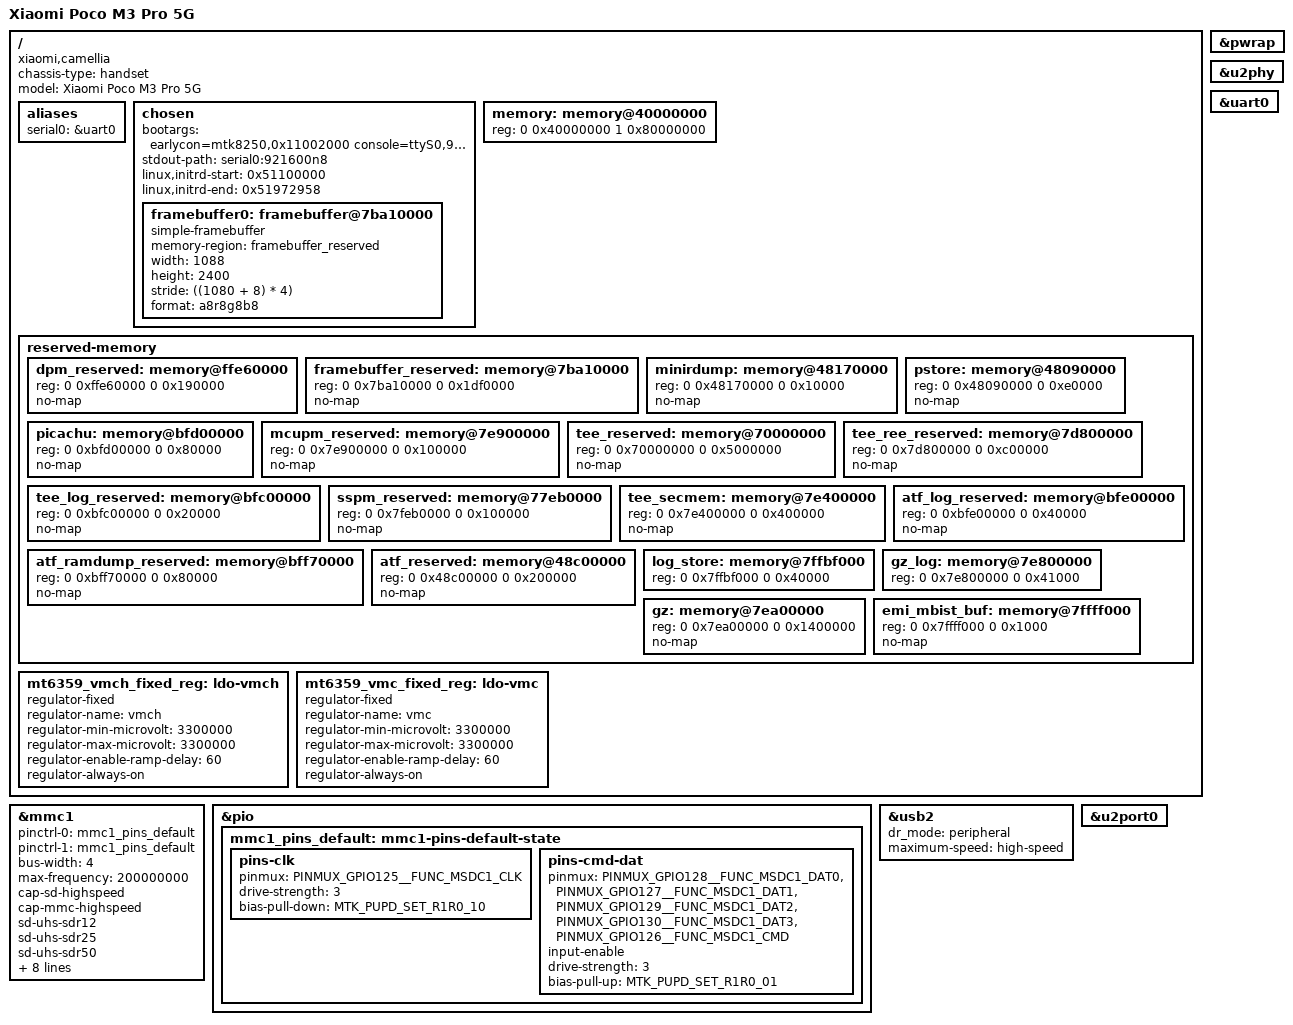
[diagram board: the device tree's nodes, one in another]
// SPDX-License-Identifier: GPL-2.0
/*
 * Device Tree Source for Xiaomi Poco M3 Pro 5G // (camellia)
 * 
 * !NEEDS TESTING FROM SIMILLAR DEVICE = Xiaomi Redmi Mote 10 Pro 5G // (camellian)
 *
 * Copyright (c) Ryo "evilMyQueen" Yamada <evilMyQueen@mainlining.org>
 */

/dts-v1/;

#include <dt-bindings/gpio/gpio.h>
#include <dt-bindings/iio/adc/mediatek,mt6370_adc.h>
#include <dt-bindings/input/input.h>
#include <dt-bindings/leds/common.h>
#include <dt-bindings/pinctrl/mediatek,mt6833-pinfunc.h>

#include "mt6833.dtsi"
#include "mt6359.dtsi"

/ {
	chassis-type = "handset";
	compatible = "xiaomi,camellia", "mediatek,mt6833";
	model = "Xiaomi Poco M3 Pro 5G";

	aliases {
		serial0 = &uart0;
	};

	chosen {
		#address-cells = <2>;
		#size-cells = <2>;
		ranges;

		bootargs = "earlycon=mtk8250,0x11002000 console=ttyS0,921600n1 console=tty0 console=ttyGS0 clk_ignore_unused regulator_ignore_unused pd_ignore_unused PMOS_NOSPLASH";
		stdout-path = "serial0:921600n8";
		linux,initrd-start = <0x51100000>;
		linux,initrd-end = <0x51972958>;
		
		framebuffer0: framebuffer@7ba10000 {
			compatible = "simple-framebuffer";
			memory-region = <&framebuffer_reserved>;
			width = <1088>;
			height = <2400>;
			stride = <((1080 + 8) * 4)>;
			format = "a8r8g8b8";
			status = "okay";
		};
	};

	memory: memory@40000000 {
		device_type = "memory";
		reg = <0 0x40000000 1 0x80000000>;
	};

	reserved-memory {
		#address-cells = <2>;
		#size-cells = <2>;
		ranges;
		
		dpm_reserved: memory@ffe60000 {
			reg = <0 0xffe60000 0 0x190000>;
			no-map;
		};

		framebuffer_reserved: memory@7ba10000 {
			reg = <0 0x7ba10000 0 0x1df0000>;
			no-map;
		};

		minirdump: memory@48170000 {
			reg = <0 0x48170000 0 0x10000>;
			no-map;
		};

		pstore: memory@48090000 {
			reg = <0 0x48090000 0 0xe0000>;
			no-map;
		};

		picachu: memory@bfd00000 {
			reg = <0 0xbfd00000 0 0x80000>;
			no-map;
		};

		mcupm_reserved: memory@7e900000 {
			reg = <0 0x7e900000 0 0x100000>;
			no-map;
		};

		tee_reserved: memory@70000000 {
			reg = <0 0x70000000 0 0x5000000>;
			no-map;
		};

		tee_ree_reserved: memory@7d800000 {
			reg = <0 0x7d800000 0 0xc00000>;
			no-map;
		};

		tee_log_reserved: memory@bfc00000 {
			reg = <0 0xbfc00000 0 0x20000>;
			no-map;
		};

		sspm_reserved: memory@77eb0000 {
			reg = <0 0x7feb0000 0 0x100000>;
			no-map;
		};

		tee_secmem: memory@7e400000 {
			reg = <0 0x7e400000 0 0x400000>;
			no-map;
		};

		atf_log_reserved: memory@bfe00000 {
			reg = <0 0xbfe00000 0 0x40000>;
			no-map;
		};

		atf_ramdump_reserved: memory@bff70000 {
			reg = <0 0xbff70000 0 0x80000>;
			no-map;
		};

		atf_reserved: memory@48c00000 {
			reg = <0 0x48c00000 0 0x200000>;
			no-map;
		};

		log_store: memory@7ffbf000 {
			reg = <0 0x7ffbf000 0 0x40000>;
		};

		gz_log: memory@7e800000 {
			reg = <0 0x7e800000 0 0x41000>;
		};

		gz: memory@7ea00000 {
			reg = <0 0x7ea00000 0 0x1400000>;
			no-map;
		};

		emi_mbist_buf: memory@7ffff000 {
			reg = <0 0x7ffff000 0 0x1000>;
			no-map;
		};
	};

	mt6359_vmch_fixed_reg: ldo-vmch {
		compatible = "regulator-fixed";
		regulator-name = "vmch";
		regulator-min-microvolt = <3300000>;
		regulator-max-microvolt = <3300000>;
		regulator-enable-ramp-delay = <60>;
		regulator-always-on;
	};

	mt6359_vmc_fixed_reg: ldo-vmc {
		compatible = "regulator-fixed";
		regulator-name = "vmc";
		regulator-min-microvolt = <3300000>;
		regulator-max-microvolt = <3300000>;
		regulator-enable-ramp-delay = <60>;
		regulator-always-on;
	};

	/* gpio_keys: gpio-keys {
		compatible = "gpio-keys";
		pinctrl-0 = <&key_gpio_default>;
		pinctrl-names = "default";

		voldown-key {
			label = "Volume Down";
			linux,code = <KEY_VOLUMEDOWN>;
			gpios = <&pio 54 GPIO_ACTIVE_LOW>;
		};
	}; */
}; 

&pwrap {
	status = "okay";
};

&mmc1 {
	status = "okay";
	pinctrl-names = "default", "state_uhs";
	pinctrl-0 = <&mmc1_pins_default>;
	pinctrl-1 = <&mmc1_pins_default>;
	bus-width = <4>;
	max-frequency = <200000000>;
	cap-sd-highspeed;
	cap-mmc-highspeed;
	sd-uhs-sdr12;
	sd-uhs-sdr25;
	sd-uhs-sdr50;
	sd-uhs-sdr104;
	sd-uhs-ddr50;
	mmc-ddr-1_8v;
	mmc-hs200-1_8v;
	no-sdio;
	cd-gpios = <&pio 4 GPIO_ACTIVE_HIGH>;
	vmmc-supply = <&mt6359_vmch_fixed_reg>; /* HACK = fake vmch vbus instead of upstream mt6359 pmic */
	vqmmc-supply = <&mt6359_vmc_fixed_reg>; /* HACK = fake vmc vbus instead of upstream m6359 pmic */
};

/* Lord please help me, WHY THE SDCARD ARENT WORKING */

&pio {
	mmc1_pins_default: mmc1-pins-default-state {
		pins-clk {
			pinmux = <PINMUX_GPIO125__FUNC_MSDC1_CLK>;
			drive-strength = <3>;
			bias-pull-down = <MTK_PUPD_SET_R1R0_10>;
		};

		pins-cmd-dat {
			pinmux = <PINMUX_GPIO128__FUNC_MSDC1_DAT0>,
					 <PINMUX_GPIO127__FUNC_MSDC1_DAT1>,
					 <PINMUX_GPIO129__FUNC_MSDC1_DAT2>,
					 <PINMUX_GPIO130__FUNC_MSDC1_DAT3>,
					 <PINMUX_GPIO126__FUNC_MSDC1_CMD>;
			input-enable;
			drive-strength = <3>;
			bias-pull-up = <MTK_PUPD_SET_R1R0_01>;
		};
	};
};

&usb2 {
	status = "okay";
	dr_mode = "peripheral";
	maximum-speed = "high-speed";
};

&u2phy {
	status = "okay";
};

&u2port0 {
	status = "okay";
};

&uart0 {
	status = "okay";
};
